# A31G33x register map
Vendor: VENDOR ABOV Semiconductor Co., Ltd.; Series: A31G33x; File version: 1.0
CPU: CM0+ r0p1, little endian, no MPU, no FPU, VTOR, 2 interrupt priority bits
Registers are 32-bit, read-only, no defined reset value unless marked. A register's access mark holds for its fields unless they carry their own. Offsets are from the block's base; [hi:lo] are bit positions; {n}, {i} and the like mark numbered series; 'fields as' and 'values as' point back to an identical list.

## Pn — Port Control Unit & GPIO Port n
Base 0x50000000
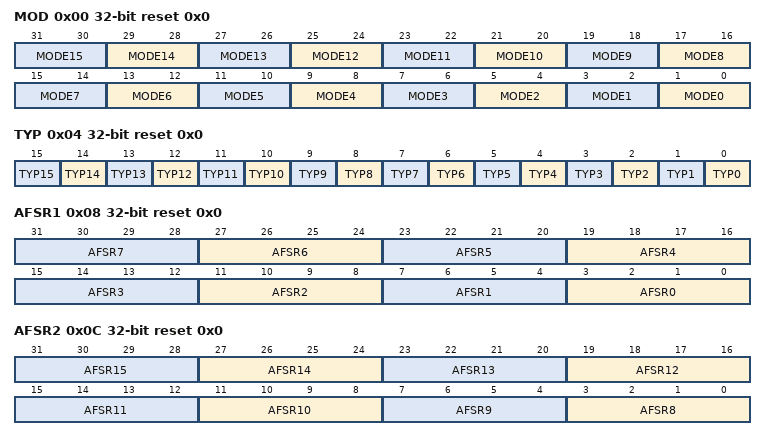
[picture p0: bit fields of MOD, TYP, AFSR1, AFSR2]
0x00 MOD rw reset 0x0 — Port n Mode Register
  [all] fields
    0=Input Mode; 1=Output Mode; 2=Alternative Function Mode
  [2n+1:2n] MODE{n} (n=0..15) — Port n Mode Selection {n}
0x04 TYP rw reset 0x0 — Port n Output Type Selection Register
  [all] fields
    0=Push-Pull Output; 1=Open-Drain Output
  [n] TYP{n} (n=0..15) — Port n Output Type Selection {n}
0x08 AFSR1 rw reset 0x0 — Port n Alternative Function Selection Register 1
  [all] fields
    {v}=AF{v} (Alternative Function {v} (AF{v})) (v=0..7)
  [4n+3:4n] AFSR{n} (n=0..7) — Port n Alternative Function Selection {n}
0x0C AFSR2 rw reset 0x0 — Port n Alternative Function Selection Register 2
  [all] fields
    {v}=AF{v} (Alternative Function {v} (AF{v})) (v=0..7)
  [4n-29:4n-32] AFSR{n} (n=8..15) — Port n Alternative Function Selection {n}
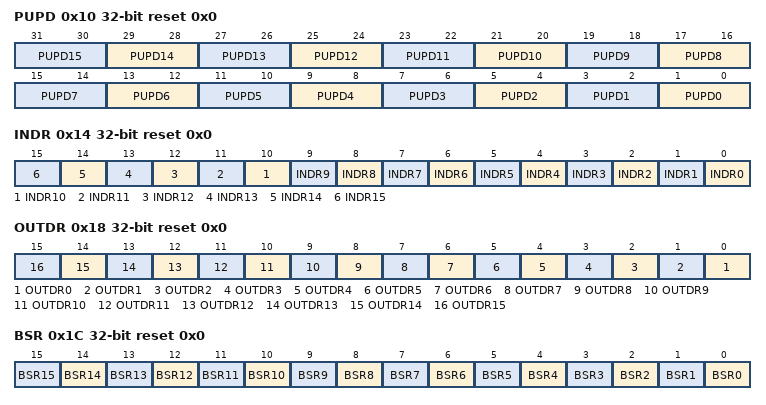
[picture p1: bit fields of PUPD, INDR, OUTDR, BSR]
0x10 PUPD rw reset 0x0 — Port n Pull-Up/Down Resistor Selection Register
  [all] fields
    0=Disable pull-up/down resistor; 1=Enable pull-up resistor; 2=EnablePD (Enable pull-down resistor.)
  [2n+1:2n] PUPD{n} (n=0..15) — Port n Pull-Up/Down Resistor Selection {n}
0x14 INDR reset 0x0 — Port n Input Data Register
  [n] INDR{n} (n=0..15) — Port n Input Data {n}
0x18 OUTDR rw reset 0x0 — Port n Output Data Register
  [n] OUTDR{n} (n=0..15) — Port n Output Data {n}
0x1C BSR wo reset 0x0 — Port n Output Bit Set Register
  [all] fields
    0=NoEffect; 1=Set (Set the corresponding OUTDRx bit (Automatically cleared to 0.))
  [n] BSR{n} (n=0..15) — Port n Output Bit Set {n}
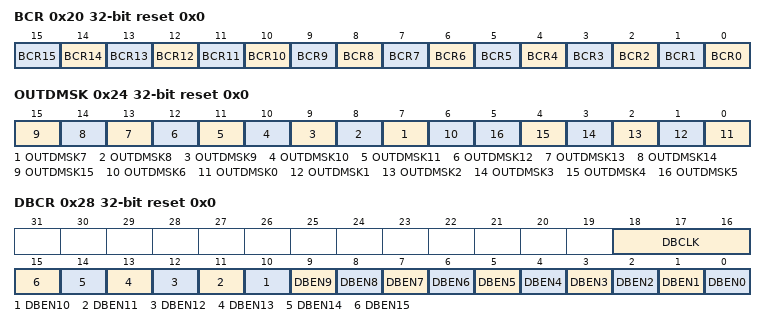
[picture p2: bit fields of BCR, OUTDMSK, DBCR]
0x20 BCR wo reset 0x0 — Port n Output Bit Clear Register
  [all] fields
    0=NoEffect; 1=Clear the corresponding OUTDRx bit. (Automatically cleared to 0.)
  [n] BCR{n} (n=0..15) — Port n Output Bit Clear {n}
0x24 OUTDMSK rw reset 0x0 — Port n Output Data Mask Register
  [n] OUTDMSK{n} (n=7..15) — Port n Output Data Mask {n}
    0=Unmask. The corresponding OUTDRx bit can be changed.; 1=Mask. The corresponding OUTDRx bit is protected.
  [6] OUTDMSK6 — Port n Output Data Mask 6
  [n] OUTDMSK{n} (n=0..5) — Port n Output Data Mask {n}
    values as OUTDMSK7
0x28 DBCR rw reset 0x0 — Port n Debounce Control Register
  [18:16] DBCLK — Port n Debounce Filter Sampling Clock Selection
    0=HCLK1; 1=HCLK4; 2=HCLK16; 3=HCLK64; 4=HCLK256; 5=HCLK1024
  [n] DBEN{n} (n=0..15) — Port n Debounce Enable {n}
    0=Disable debounce filter; 1=Enable debounce filter

## PB — Port Control Unit & GPIO Port B
Base 0x30000100
Registers as Pn; these are added or differ:
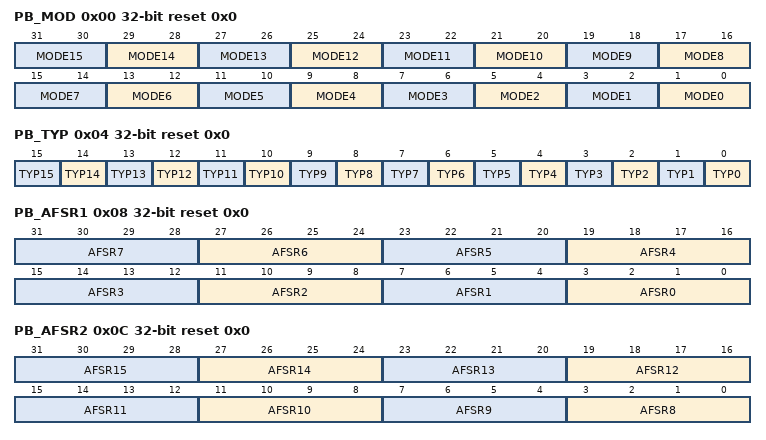
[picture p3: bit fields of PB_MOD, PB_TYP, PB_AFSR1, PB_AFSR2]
0x00 PB_MOD rw reset 0x0 (alternate view of MOD) — Port n Mode Register
  [2n+1:2n] MODE{n} (n=0..15) — Port n Mode Selection {n}
0x04 PB_TYP rw reset 0x0 (alternate view of TYP) — Port n Output Type Selection Register
  [n] TYP{n} (n=0..15) — Port n Output Type Selection {n}
0x08 PB_AFSR1 rw reset 0x0 (alternate view of AFSR1) — Port n Alternative Function Selection Register 1
  [4n+3:4n] AFSR{n} (n=0..7) — Port n Alternative Function Selection {n}
0x0C PB_AFSR2 rw reset 0x0 (alternate view of AFSR2) — Port n Alternative Function Selection Register 2
  [4n-29:4n-32] AFSR{n} (n=8..15) — Port n Alternative Function Selection {n}
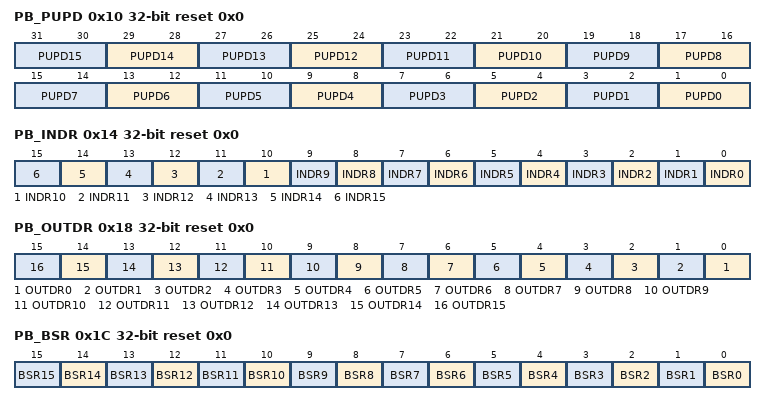
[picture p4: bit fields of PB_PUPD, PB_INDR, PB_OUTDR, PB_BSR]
0x10 PB_PUPD rw reset 0x0 (alternate view of PUPD) — Port n Pull-Up/Down Resistor Selection Register
  [2n+1:2n] PUPD{n} (n=0..15) — Port n Pull-Up/Down Resistor Selection {n}
0x14 PB_INDR reset 0x0 (alternate view of INDR) — Port n Input Data Register
  [n] INDR{n} (n=0..15) — Port n Input Data {n}
0x18 PB_OUTDR rw reset 0x0 (alternate view of OUTDR) — Port n Output Data Register
  [n] OUTDR{n} (n=0..15) — Port n Output Data {n}
0x1C PB_BSR wo reset 0x0 (alternate view of BSR) — Port n Output Bit Set Register
  [n] BSR{n} (n=0..15) — Port n Output Bit Set {n}
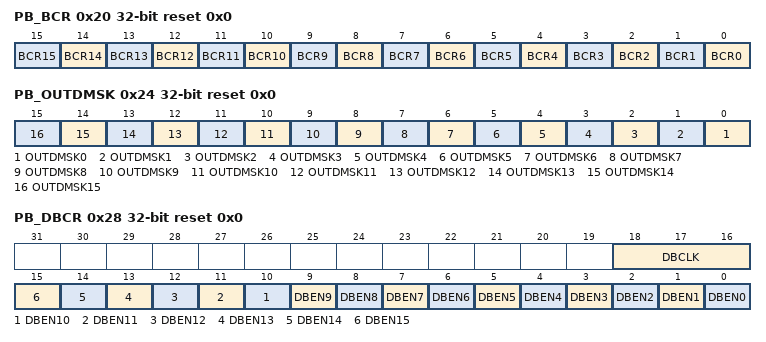
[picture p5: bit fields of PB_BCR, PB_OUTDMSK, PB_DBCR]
0x20 PB_BCR wo reset 0x0 (alternate view of BCR) — Port n Output Bit Clear Register
  [n] BCR{n} (n=0..15) — Port n Output Bit Clear {n}
0x24 PB_OUTDMSK rw reset 0x0 (alternate view of OUTDMSK) — Port n Output Data Mask Register
  [n] OUTDMSK{n} (n=0..15) — Port n Output Data Mask {n}
0x28 PB_DBCR rw reset 0x0 (alternate view of DBCR) — Port n Debounce Control Register
  [18:16] DBCLK — Port n Debounce Filter Sampling Clock Selection
  [n] DBEN{n} (n=0..15) — Port n Debounce Enable {n}

## PC — Port Control Unit & GPIO Port C
Base 0x30000200
Registers as Pn; these are added or differ:
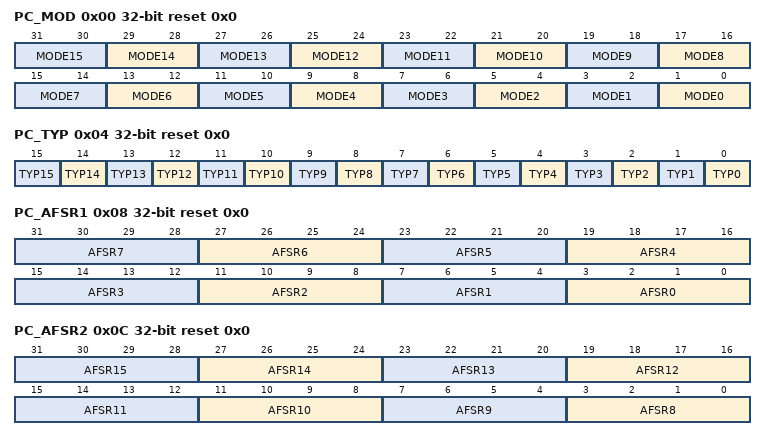
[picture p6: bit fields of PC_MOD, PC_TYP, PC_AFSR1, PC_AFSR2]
0x00 PC_MOD rw reset 0x0 (alternate view of MOD) — Port n Mode Register
  [2n+1:2n] MODE{n} (n=0..15) — Port n Mode Selection {n}
0x04 PC_TYP rw reset 0x0 (alternate view of TYP) — Port n Output Type Selection Register
  [n] TYP{n} (n=0..15) — Port n Output Type Selection {n}
0x08 PC_AFSR1 rw reset 0x0 (alternate view of AFSR1) — Port n Alternative Function Selection Register 1
  [4n+3:4n] AFSR{n} (n=0..7) — Port n Alternative Function Selection {n}
0x0C PC_AFSR2 rw reset 0x0 (alternate view of AFSR2) — Port n Alternative Function Selection Register 2
  [4n-29:4n-32] AFSR{n} (n=8..15) — Port n Alternative Function Selection {n}
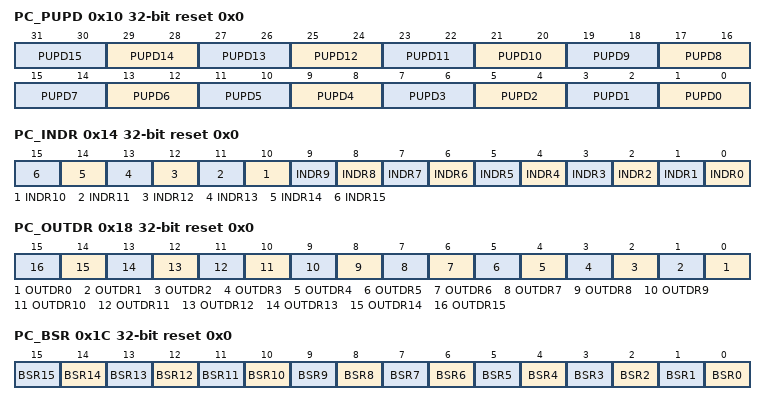
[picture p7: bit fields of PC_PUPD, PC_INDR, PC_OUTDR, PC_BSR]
0x10 PC_PUPD rw reset 0x0 (alternate view of PUPD) — Port n Pull-Up/Down Resistor Selection Register
  [2n+1:2n] PUPD{n} (n=0..15) — Port n Pull-Up/Down Resistor Selection {n}
0x14 PC_INDR reset 0x0 (alternate view of INDR) — Port n Input Data Register
  [n] INDR{n} (n=0..15) — Port n Input Data {n}
0x18 PC_OUTDR rw reset 0x0 (alternate view of OUTDR) — Port n Output Data Register
  [n] OUTDR{n} (n=0..15) — Port n Output Data {n}
0x1C PC_BSR wo reset 0x0 (alternate view of BSR) — Port n Output Bit Set Register
  [n] BSR{n} (n=0..15) — Port n Output Bit Set {n}
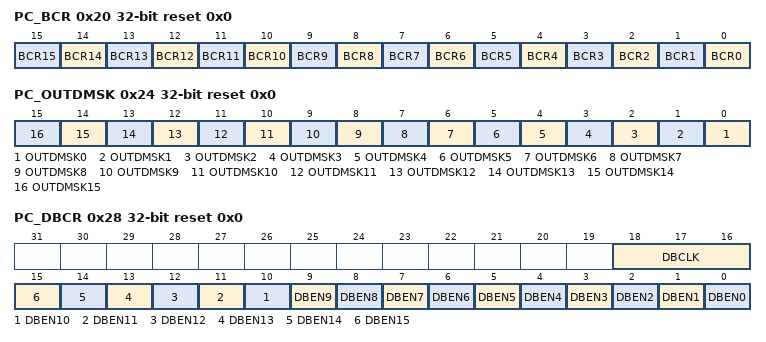
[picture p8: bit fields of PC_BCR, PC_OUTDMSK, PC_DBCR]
0x20 PC_BCR wo reset 0x0 (alternate view of BCR) — Port n Output Bit Clear Register
  [n] BCR{n} (n=0..15) — Port n Output Bit Clear {n}
0x24 PC_OUTDMSK rw reset 0x0 (alternate view of OUTDMSK) — Port n Output Data Mask Register
  [n] OUTDMSK{n} (n=0..15) — Port n Output Data Mask {n}
0x28 PC_DBCR rw reset 0x0 (alternate view of DBCR) — Port n Debounce Control Register
  [18:16] DBCLK — Port n Debounce Filter Sampling Clock Selection
  [n] DBEN{n} (n=0..15) — Port n Debounce Enable {n}

## PD — Port Control Unit & GPIO Port D
Base 0x30000300
Registers as Pn; these are added or differ:
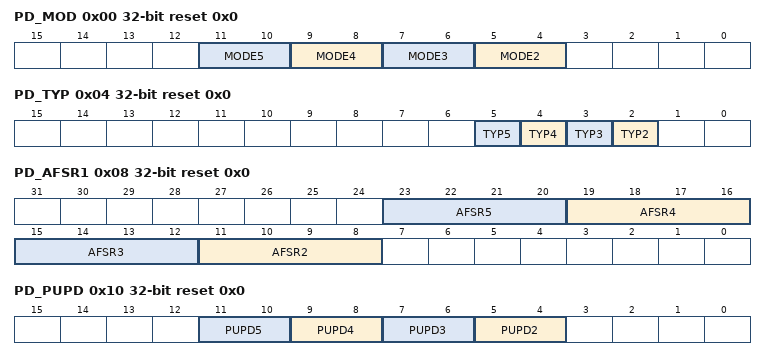
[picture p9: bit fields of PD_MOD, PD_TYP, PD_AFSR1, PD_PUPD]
0x00 PD_MOD rw reset 0x0 (alternate view of MOD) — Port n Mode Register
  [2n+1:2n] MODE{n} (n=2..5) — Port n Mode Selection {n}
0x04 PD_TYP rw reset 0x0 (alternate view of TYP) — Port n Output Type Selection Register
  [n] TYP{n} (n=2..5) — Port n Output Type Selection {n}
0x08 PD_AFSR1 rw reset 0x0 (alternate view of AFSR1) — Port n Alternative Function Selection Register 1
  [4n+3:4n] AFSR{n} (n=2..5) — Port n Alternative Function Selection {n}
0x10 PD_PUPD rw reset 0x0 (alternate view of PUPD) — Port n Pull-Up/Down Resistor Selection Register
  [2n+1:2n] PUPD{n} (n=2..5) — Port n Pull-Up/Down Resistor Selection {n}
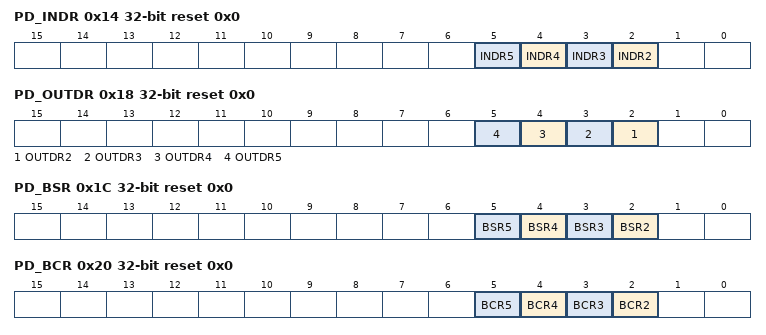
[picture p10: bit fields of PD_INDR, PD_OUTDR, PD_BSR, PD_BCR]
0x14 PD_INDR reset 0x0 (alternate view of INDR) — Port n Input Data Register
  [n] INDR{n} (n=2..5) — Port n Input Data {n}
0x18 PD_OUTDR rw reset 0x0 (alternate view of OUTDR) — Port n Output Data Register
  [n] OUTDR{n} (n=2..5) — Port n Output Data {n}
0x1C PD_BSR wo reset 0x0 (alternate view of BSR) — Port n Output Bit Set Register
  [n] BSR{n} (n=2..5) — Port n Output Bit Set {n}
0x20 PD_BCR wo reset 0x0 (alternate view of BCR) — Port n Output Bit Clear Register
  [n] BCR{n} (n=2..5) — Port n Output Bit Clear {n}
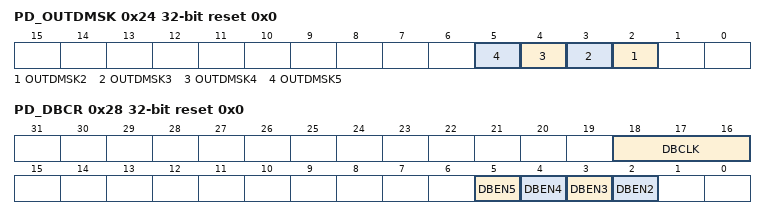
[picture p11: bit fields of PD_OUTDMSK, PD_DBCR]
0x24 PD_OUTDMSK rw reset 0x0 (alternate view of OUTDMSK) — Port n Output Data Mask Register
  [n] OUTDMSK{n} (n=2..5) — Port n Output Data Mask {n}
0x28 PD_DBCR rw reset 0x0 (alternate view of DBCR) — Port n Debounce Control Register
  [18:16] DBCLK — Port n Debounce Filter Sampling Clock Selection
  [n] DBEN{n} (n=2..5) — Port n Debounce Enable {n}

## PF — Port Control Unit & GPIO Port F
Base 0x30000500
Registers as Pn; these are added or differ:
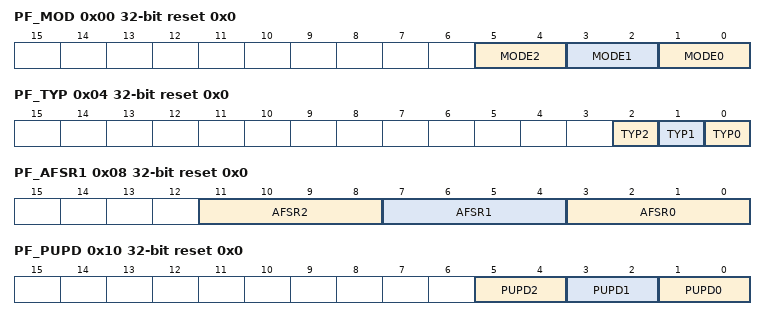
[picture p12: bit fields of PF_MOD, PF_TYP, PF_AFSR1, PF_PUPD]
0x00 PF_MOD rw reset 0x0 (alternate view of MOD) — Port n Mode Register
  [5:4] MODE2 — Port n Mode Selection 2
  [3:2] MODE1 — Port n Mode Selection 1
  [1:0] MODE0 — Port n Mode Selection 0
0x04 PF_TYP rw reset 0x0 (alternate view of TYP) — Port n Output Type Selection Register
  [2] TYP2 — Port n Output Type Selection 2
  [1] TYP1 — Port n Output Type Selection 1
  [0] TYP0 — Port n Output Type Selection 0
0x08 PF_AFSR1 rw reset 0x0 (alternate view of AFSR1) — Port n Alternative Function Selection Register 1
  [11:8] AFSR2 — Port n Alternative Function Selection 2
  [7:4] AFSR1 — Port n Alternative Function Selection 1
  [3:0] AFSR0 — Port n Alternative Function Selection 0
0x10 PF_PUPD rw reset 0x0 (alternate view of PUPD) — Port n Pull-Up/Down Resistor Selection Register
  [5:4] PUPD2 — Port n Pull-Up/Down Resistor Selection 2
  [3:2] PUPD1 — Port n Pull-Up/Down Resistor Selection 1
  [1:0] PUPD0 — Port n Pull-Up/Down Resistor Selection 0
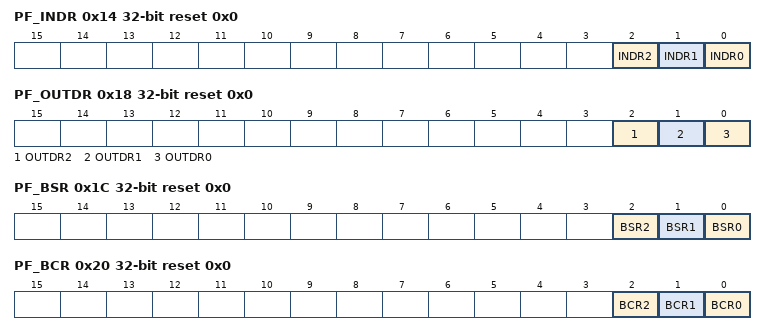
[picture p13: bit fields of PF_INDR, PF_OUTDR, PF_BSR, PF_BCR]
0x14 PF_INDR reset 0x0 (alternate view of INDR) — Port n Input Data Register
  [2] INDR2 — Port n Input Data 2
  [1] INDR1 — Port n Input Data 1
  [0] INDR0 — Port n Input Data 0
0x18 PF_OUTDR rw reset 0x0 (alternate view of OUTDR) — Port n Output Data Register
  [2] OUTDR2 — Port n Output Data 2
  [1] OUTDR1 — Port n Output Data 1
  [0] OUTDR0 — Port n Output Data 0
0x1C PF_BSR wo reset 0x0 (alternate view of BSR) — Port n Output Bit Set Register
  [2] BSR2 — Port n Output Bit Set 2
  [1] BSR1 — Port n Output Bit Set 1
  [0] BSR0 — Port n Output Bit Set 0
0x20 PF_BCR wo reset 0x0 (alternate view of BCR) — Port n Output Bit Clear Register
  [2] BCR2 — Port n Output Bit Clear 2
  [1] BCR1 — Port n Output Bit Clear 1
  [0] BCR0 — Port n Output Bit Clear 0
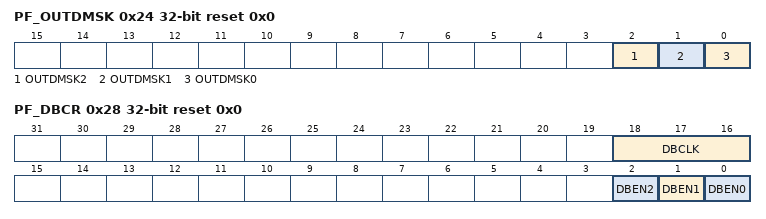
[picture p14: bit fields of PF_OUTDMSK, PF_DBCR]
0x24 PF_OUTDMSK rw reset 0x0 (alternate view of OUTDMSK) — Port n Output Data Mask Register
  [2] OUTDMSK2 — Port n Output Data Mask 2
  [1] OUTDMSK1 — Port n Output Data Mask 1
  [0] OUTDMSK0 — Port n Output Data Mask 0
0x28 PF_DBCR rw reset 0x0 (alternate view of DBCR) — Port n Debounce Control Register
  [18:16] DBCLK — Port n Debounce Filter Sampling Clock Selection
  [2] DBEN2 — Port n Debounce Enable 2
  [1] DBEN1 — Port n Debounce Enable 1
  [0] DBEN0 — Port n Debounce Enable 0
